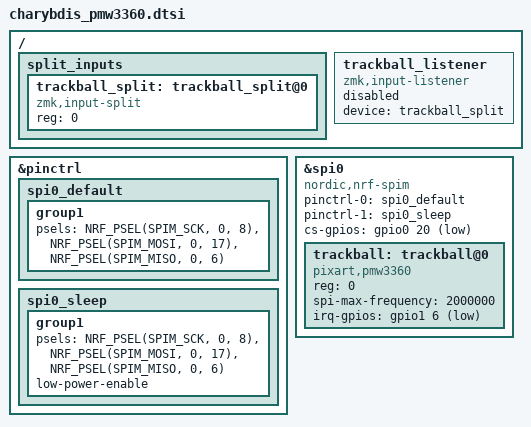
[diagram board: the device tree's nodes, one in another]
/* Sensor wiring (nice!nano D-pin labels, per PCB GPIO map):
 *   SCLK   -> D0  (P0.08)
 *   MISO   -> D1  (P0.06)  -- this pad previously carried the PMW3610's MOTION line
 *   MOSI   -> D2  (P0.17)  -- this pad previously carried the PMW3610's shared SDIO line
 *   NCS    -> D3  (P0.20)
 *   MOTION -> D9  (P1.06)  -- the unused R5 matrix row pad, required by this driver's binding
 * RESET is not wired: this driver has no reset-gpios, the sensor is reset
 * purely over SPI (NCS toggle + power-up-reset register write). Tie RESET
 * to VDDIO on the sensor board itself rather than leaving it floating.
 *
 * CPI and axis orientation (invert/rotate) are Kconfig options for this
 * driver, not devicetree properties - see the shield's .conf file.
 */
&pinctrl {
    spi0_default: spi0_default {
        group1 {
            psels = <NRF_PSEL(SPIM_SCK, 0, 8)>,
                <NRF_PSEL(SPIM_MOSI, 0, 17)>,
                <NRF_PSEL(SPIM_MISO, 0, 6)>;
        };
    };

    spi0_sleep: spi0_sleep {
        group1 {
            psels = <NRF_PSEL(SPIM_SCK, 0, 8)>,
                <NRF_PSEL(SPIM_MOSI, 0, 17)>,
                <NRF_PSEL(SPIM_MISO, 0, 6)>;
            low-power-enable;
        };
    };
};

&spi0 {
    status = "okay";
    compatible = "nordic,nrf-spim";
    pinctrl-0 = <&spi0_default>;
    pinctrl-1 = <&spi0_sleep>;
    pinctrl-names = "default", "sleep";
    cs-gpios = <&gpio0 20 GPIO_ACTIVE_LOW>;

    trackball: trackball@0 {
        status = "okay";
        compatible = "pixart,pmw3360";
        reg = <0>;
        spi-max-frequency = <2000000>;
        irq-gpios = <&gpio1 6 (GPIO_ACTIVE_LOW | GPIO_PULL_UP)>;
    };
};

/ {
    split_inputs {
        #address-cells = <1>;
        #size-cells = <0>;

        trackball_split: trackball_split@0 {
            compatible = "zmk,input-split";
            reg = <0>;
        };
    };

    trackball_listener: trackball_listener {
        compatible = "zmk,input-listener";
        status = "disabled"; // overridden on central
        device = <&trackball_split>;
    };
};
